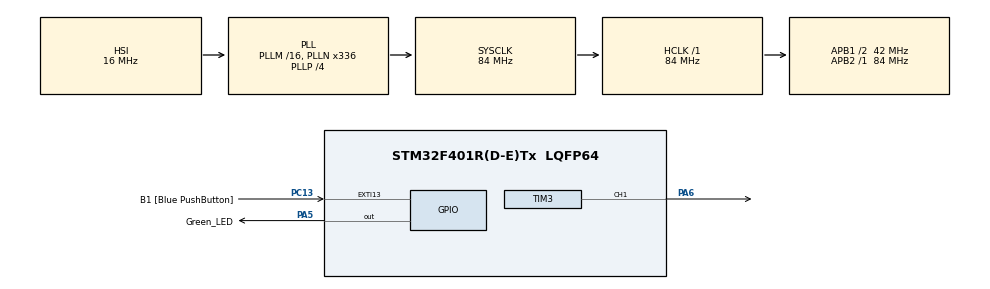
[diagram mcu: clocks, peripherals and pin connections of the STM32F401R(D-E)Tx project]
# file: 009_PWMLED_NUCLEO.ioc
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Mcu.Family=STM32F4
Mcu.Name=STM32F401R(D-E)Tx
Mcu.Package=LQFP64
NVIC.PriorityGroup=NVIC_PRIORITYGROUP_0
PA13.GPIO_Label=TMS
PA13.Signal=SYS_JTMS-SWDIO
PA14.GPIO_Label=TCK
PA14.Signal=SYS_JTCK-SWCLK
PA2.GPIO_Label=USART_TX
PA2.GPIO_Mode=GPIO_MODE_AF_PP
PA2.GPIO_PuPd=GPIO_NOPULL
PA2.GPIO_Speed=GPIO_SPEED_FREQ_LOW
PA2.Signal=USART2_TX
PA3.GPIO_Label=USART_RX
PA3.GPIO_Mode=GPIO_MODE_AF_PP
PA3.GPIO_PuPd=GPIO_NOPULL
PA3.GPIO_Speed=GPIO_SPEED_FREQ_LOW
PA3.Signal=USART2_RX
PA5.GPIO_Label=Green_LED
PA5.GPIO_Mode=GPIO_MODE_OUTPUT_PP
PA5.GPIO_PuPd=GPIO_NOPULL
PA5.GPIO_Speed=GPIO_SPEED_FREQ_LOW
PA5.Signal=GPIO_Output
PA6.GPIO_PuPd=GPIO_PULLUP
PA6.Signal=S_TIM3_CH1
PB3.GPIO_Label=SWO
PB3.Signal=SYS_JTDO-SWO
PC13-ANTI_TAMP.GPIO_Label=B1 [Blue PushButton]
PC13-ANTI_TAMP.GPIO_ModeDefaultEXTI=GPIO_MODE_IT_FALLING
PC13-ANTI_TAMP.GPIO_PuPd=GPIO_NOPULL
PC13-ANTI_TAMP.Signal=GPXTI13
PC14-OSC32_IN.Signal=RCC_OSC32_IN
PC15-OSC32_OUT.Signal=RCC_OSC32_OUT
PH0\ -\ OSC_IN.Signal=RCC_OSC_IN
PH1\ -\ OSC_OUT.Signal=RCC_OSC_OUT
ProjectManager.HeapSize=0x200
ProjectManager.StackSize=0x400
ProjectManager.TargetToolchain=MDK-ARM V5.32
RCC.AHBFreq_Value=84000000
RCC.APB1CLKDivider=RCC_HCLK_DIV2
RCC.APB1Freq_Value=42000000
RCC.APB1TimFreq_Value=84000000
RCC.APB2Freq_Value=84000000
RCC.APB2TimFreq_Value=84000000
RCC.CortexFreq_Value=84000000
RCC.HCLKFreq_Value=84000000
RCC.HSE_VALUE=8000000
RCC.HSI_VALUE=16000000
RCC.LSE_VALUE=32768
RCC.PLLN=336
RCC.PLLP=RCC_PLLP_DIV4
RCC.PLLQ=7
RCC.SYSCLKFreq_VALUE=84000000
RCC.SYSCLKSource=RCC_SYSCLKSOURCE_PLLCLK
RCC.VCOOutputFreq_Value=336000000
SH.S_TIM3_CH1.0=TIM3_CH1,PWM Generation1 CH1
TIM3.Channel-PWM\ Generation1\ CH1=TIM_CHANNEL_1
TIM3.Period=65535
TIM3.Prescaler=0
TIM3.Pulse-PWM\ Generation1\ CH1=0
board=NUCLEO-F401RE

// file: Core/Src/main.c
/* USER CODE BEGIN Header */
/**
  ******************************************************************************
  * @file           : main.c
  * @brief          : Main program body
  ******************************************************************************
  * @attention
  *
  * <h2><center>&copy; Copyright (c) 2021 STMicroelectronics.
  * All rights reserved.</center></h2>
  *
  * This software component is licensed by ST under BSD 3-Clause license,
  * the "License"; You may not use this file except in compliance with the
  * License. You may obtain a copy of the License at:
  *                        opensource.org/licenses/BSD-3-Clause
  *
  ******************************************************************************
  */
/* USER CODE END Header */
#include "main.h"
#include "tim.h"
#include "gpio.h"

void SystemClock_Config(void);

/* USER CODE BEGIN 0 */
	int32_t A=0;
/* USER CODE END 0 */

int main(void)
{

  /* MCU Configuration--------------------------------------------------------*/

  /* Reset of all peripherals, Initializes the Flash interface and the Systick. */
  HAL_Init();

  /* Configure the system clock */
  SystemClock_Config();

  /* Initialize all configured peripherals */
  MX_GPIO_Init();
  MX_TIM3_Init();
  /* USER CODE BEGIN 2 */
	HAL_TIM_PWM_Start(&htim3,TIM_CHANNEL_1);

	/*

	>>>PWM Frequency Set-up
	 -Defined With auto-reload(ARR, in TIM_ARR) and clock prescaler(PSC,TIMx_PSC)

			 Fpwm = Ftim / (ARR+1) * (PSC+1)

	Fpwm=PWM Freq
	Ftim= Timer Freq
	ARR= Auto Reload Register ( Counter Period)
	PSC= Prescaler

	-Practically, one must start with PSC=0(no prescaler)

				ARR= (Ftim / Fpwm) - 1

	-If it yields a value above the 16 bit(or 32 bit) range, PSC must be increased until ARR fits:

				ARR = ( (Ftim/2) / Fpwm ) -1 -> ARR = ( (Ftim/3) / Fpwm ) -1 -> ARR = ( (Ftim/4) / Fpwm ) -1 ->...

	>>>Duty Cycle Set-up

			Duty Cycle = (CCRx+1) / (ARR+1)

			CCRx = (Duty Cycle x (ARR+1))-1

	    CCRx = Pulse (in Cubemx) (Capture/Compare Register)

	>>> PWM resolution

	-The resolution gives the number of possible duty cycle values and indicates how fine the control on the PWM signal will be:

			Res(steps) = Ftim / Fpwm

	-Another way of expressing it is in bits, as for giving a DAC converter output resolution:

			Res(bits) = log2(Ftim/Fpwm)    ** 2 is base for log

	*/

  /* USER CODE END 2 */

  /* Infinite loop */
  while (1)
  {

    /* USER CODE BEGIN 3 */

		TIM3->CCR1=A;
		A=A+500;
		if(A>65000)
		{
				A=0;
		}
		HAL_Delay(100);

  }
  /* USER CODE END 3 */
}

void SystemClock_Config(void)
{
  RCC_OscInitTypeDef RCC_OscInitStruct = {0};
  RCC_ClkInitTypeDef RCC_ClkInitStruct = {0};

  /** Configure the main internal regulator output voltage
  */
  __HAL_RCC_PWR_CLK_ENABLE();
  __HAL_PWR_VOLTAGESCALING_CONFIG(PWR_REGULATOR_VOLTAGE_SCALE2);
  /** Initializes the RCC Oscillators according to the specified parameters
  * in the RCC_OscInitTypeDef structure.
  */
  RCC_OscInitStruct.OscillatorType = RCC_OSCILLATORTYPE_HSI;
  RCC_OscInitStruct.HSIState = RCC_HSI_ON;
  RCC_OscInitStruct.HSICalibrationValue = RCC_HSICALIBRATION_DEFAULT;
  RCC_OscInitStruct.PLL.PLLState = RCC_PLL_ON;
  RCC_OscInitStruct.PLL.PLLSource = RCC_PLLSOURCE_HSI;
  RCC_OscInitStruct.PLL.PLLM = 16;
  RCC_OscInitStruct.PLL.PLLN = 336;
  RCC_OscInitStruct.PLL.PLLP = RCC_PLLP_DIV4;
  RCC_OscInitStruct.PLL.PLLQ = 7;
  if (HAL_RCC_OscConfig(&RCC_OscInitStruct) != HAL_OK)
  {
    Error_Handler();
  }
  /** Initializes the CPU, AHB and APB buses clocks
  */
  RCC_ClkInitStruct.ClockType = RCC_CLOCKTYPE_HCLK|RCC_CLOCKTYPE_SYSCLK
                              |RCC_CLOCKTYPE_PCLK1|RCC_CLOCKTYPE_PCLK2;
  RCC_ClkInitStruct.SYSCLKSource = RCC_SYSCLKSOURCE_PLLCLK;
  RCC_ClkInitStruct.AHBCLKDivider = RCC_SYSCLK_DIV1;
  RCC_ClkInitStruct.APB1CLKDivider = RCC_HCLK_DIV2;
  RCC_ClkInitStruct.APB2CLKDivider = RCC_HCLK_DIV1;

  if (HAL_RCC_ClockConfig(&RCC_ClkInitStruct, FLASH_LATENCY_2) != HAL_OK)
  {
    Error_Handler();
  }
}

void Error_Handler(void)
{
  __disable_irq();
  while (1)
  {
  }
}

/************************ (C) COPYRIGHT STMicroelectronics *****END OF FILE****/
